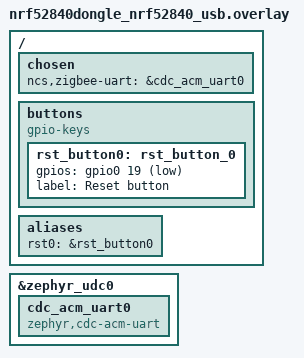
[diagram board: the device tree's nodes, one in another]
/*
 * Copyright (c) 2021 Nordic Semiconductor ASA
 *
 * SPDX-License-Identifier: LicenseRef-Nordic-5-Clause
 */

&zephyr_udc0 {
	cdc_acm_uart0: cdc_acm_uart0 {
		compatible = "zephyr,cdc-acm-uart";
	};
};

/ {
	chosen {
		ncs,zigbee-uart = &cdc_acm_uart0;
	};

	buttons {
		compatible = "gpio-keys";
		rst_button0: rst_button_0 {
			gpios = <&gpio0 19 (GPIO_PULL_UP | GPIO_ACTIVE_LOW)>;
			label = "Reset button";
		};
	};

	aliases {
		rst0 = &rst_button0;
	};
};
